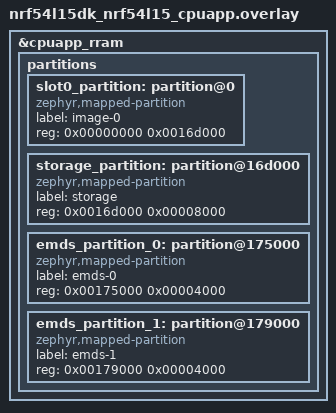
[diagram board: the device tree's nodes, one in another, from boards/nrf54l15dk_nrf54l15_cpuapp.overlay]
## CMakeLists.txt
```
#
# Copyright (c) 2020 Nordic Semiconductor ASA
#
# SPDX-License-Identifier: LicenseRef-Nordic-5-Clause
#
cmake_minimum_required(VERSION 3.20.0)

find_package(Zephyr REQUIRED HINTS $ENV{ZEPHYR_BASE})
project(NONE)

target_sources(app PRIVATE src/main.c)
```

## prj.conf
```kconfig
#
# Copyright (c) 2020 Nordic Semiconductor ASA
#
# SPDX-License-Identifier: LicenseRef-Nordic-5-Clause
#
CONFIG_NCS_SAMPLES_DEFAULTS=y
CONFIG_LOG_MODE_DEFERRED=y

# General configuration
CONFIG_SYSTEM_WORKQUEUE_STACK_SIZE=2048
CONFIG_FLASH=y
CONFIG_FLASH_MAP=y
CONFIG_FCB=y
CONFIG_SETTINGS=y
CONFIG_FPU=y

# Bluetooth configuration
CONFIG_BT=y
CONFIG_BT_L2CAP_TX_MTU=69
CONFIG_BT_L2CAP_TX_BUF_COUNT=8
CONFIG_BT_OBSERVER=y
CONFIG_BT_PERIPHERAL=y

# Bluetooth Mesh configuration
CONFIG_BT_MESH=y
CONFIG_BT_MESH_RELAY=y
CONFIG_BT_MESH_FRIEND=y
CONFIG_BT_MESH_LOW_POWER=y
CONFIG_BT_MESH_PB_GATT=y
CONFIG_BT_MESH_GATT_PROXY=y

# Bluetooth Mesh models
CONFIG_BT_MESH_ONOFF_SRV=y
CONFIG_BT_MESH_ONOFF_CLI=y
CONFIG_BT_MESH_TIME_SRV=y
CONFIG_BT_MESH_TIME_CLI=y
CONFIG_BT_MESH_LVL_SRV=y
CONFIG_BT_MESH_LVL_CLI=y
CONFIG_BT_MESH_DTT_SRV=y
CONFIG_BT_MESH_DTT_CLI=y
CONFIG_BT_MESH_PONOFF_SRV=y
CONFIG_BT_MESH_PONOFF_CLI=y
CONFIG_BT_MESH_PLVL_SRV=y
CONFIG_BT_MESH_PLVL_CLI=y
CONFIG_BT_MESH_BATTERY_SRV=y
CONFIG_BT_MESH_BATTERY_CLI=y
CONFIG_BT_MESH_LOC_SRV=y
CONFIG_BT_MESH_LOC_CLI=y
CONFIG_BT_MESH_PROP_SRV=y
CONFIG_BT_MESH_PROP_CLI=y
CONFIG_BT_MESH_LIGHTNESS_SRV=y
CONFIG_BT_MESH_LIGHTNESS_CLI=y
CONFIG_BT_MESH_LIGHT_CTRL_SRV=y
CONFIG_BT_MESH_LIGHT_CTRL_CLI=y
CONFIG_BT_MESH_LIGHT_CTL_CLI=y
CONFIG_BT_MESH_LIGHT_CTL_SRV=y
CONFIG_BT_MESH_LIGHT_TEMP_SRV=y
CONFIG_BT_MESH_SENSOR_SRV=y
CONFIG_BT_MESH_SENSOR_CLI=y
CONFIG_BT_MESH_SCENE_CLI=y
CONFIG_BT_MESH_LIGHT_XYL_SRV=y
CONFIG_BT_MESH_LIGHT_XYL_CLI=y
CONFIG_BT_MESH_LIGHT_HUE_SRV=y
CONFIG_BT_MESH_LIGHT_SAT_SRV=y
CONFIG_BT_MESH_LIGHT_HSL_SRV=y
CONFIG_BT_MESH_LIGHT_HSL_CLI=y
CONFIG_BT_MESH_SCHEDULER_CLI=y
```

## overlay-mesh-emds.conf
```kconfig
#
# Copyright (c) 2024 Nordic Semiconductor ASA
#
# SPDX-License-Identifier: LicenseRef-Nordic-5-Clause
#

CONFIG_BT_SETTINGS=y
CONFIG_FLASH_MAP=y
CONFIG_NVS=y
CONFIG_EMDS=y
CONFIG_BT_MESH_PLVL_SRV=y
CONFIG_BT_MESH_LIGHT_HUE_SRV=y
CONFIG_BT_MESH_LIGHT_SAT_SRV=y
CONFIG_BT_MESH_LIGHT_TEMP_SRV=y
CONFIG_BT_MESH_LIGHT_XYL_SRV=y
CONFIG_BT_MESH_LIGHTNESS_SRV=y
CONFIG_BT_MESH_ONOFF_SRV=n
CONFIG_BT_MESH_ONOFF_CLI=n
CONFIG_BT_MESH_TIME_SRV=n
CONFIG_BT_MESH_TIME_CLI=n
CONFIG_BT_MESH_LVL_SRV=n
CONFIG_BT_MESH_LVL_CLI=n
CONFIG_BT_MESH_DTT_SRV=n
CONFIG_BT_MESH_DTT_CLI=n
CONFIG_BT_MESH_PONOFF_SRV=n
CONFIG_BT_MESH_PONOFF_CLI=n
CONFIG_BT_MESH_PLVL_CLI=n
CONFIG_BT_MESH_BATTERY_SRV=n
CONFIG_BT_MESH_BATTERY_CLI=n
CONFIG_BT_MESH_LOC_SRV=n
CONFIG_BT_MESH_LOC_CLI=n
CONFIG_BT_MESH_PROP_SRV=n
CONFIG_BT_MESH_PROP_CLI=n
CONFIG_BT_MESH_LIGHTNESS_CLI=n
CONFIG_BT_MESH_LIGHT_CTRL_SRV=y
CONFIG_BT_MESH_LIGHT_CTRL_CLI=n
CONFIG_BT_MESH_LIGHT_CTL_CLI=n
CONFIG_BT_MESH_LIGHT_CTL_SRV=n
CONFIG_BT_MESH_SENSOR_SRV=n
CONFIG_BT_MESH_SENSOR_CLI=n
CONFIG_BT_MESH_SCENE_CLI=n
CONFIG_BT_MESH_LIGHT_XYL_CLI=n
CONFIG_BT_MESH_LIGHT_HSL_SRV=n
CONFIG_BT_MESH_LIGHT_HSL_CLI=n
```

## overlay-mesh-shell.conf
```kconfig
#
# Copyright (c) 2024 Nordic Semiconductor ASA
#
# SPDX-License-Identifier: LicenseRef-Nordic-5-Clause
#

CONFIG_BT_MESH_SHELL=y
CONFIG_BT_MESH_SHELL_ONOFF_CLI=y
CONFIG_BT_MESH_SHELL_LVL_CLI=y
CONFIG_BT_MESH_SHELL_DTT_CLI=y
CONFIG_BT_MESH_SHELL_PONOFF_CLI=y
CONFIG_BT_MESH_SHELL_PLVL_CLI=y
CONFIG_BT_MESH_SHELL_BATTERY_CLI=y
CONFIG_BT_MESH_SHELL_LOC_CLI=y
CONFIG_BT_MESH_SHELL_PROP_CLI=y
CONFIG_BT_MESH_SHELL_LIGHTNESS_CLI=y
CONFIG_BT_MESH_SHELL_LIGHT_CTL_CLI=y
CONFIG_BT_MESH_SHELL_LIGHT_HSL_CLI=y
CONFIG_BT_MESH_SHELL_LIGHT_XYL_CLI=y
CONFIG_BT_MESH_SHELL_LIGHT_CTRL_CLI=y
CONFIG_BT_MESH_SHELL_TIME_CLI=y
CONFIG_BT_MESH_SHELL_SCENE_CLI=y
CONFIG_BT_MESH_SHELL_SCHEDULER_CLI=y
CONFIG_BT_MESH_SHELL_SENSOR_CLI=y
```

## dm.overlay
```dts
/*
 * Copyright (c) 2024 Nordic Semiconductor ASA
 *
 * SPDX-License-Identifier: LicenseRef-Nordic-5-Clause
 */

/ {
	/* The timer instance to use. */
	chosen {
		ncs,dm-timer = &timer2;
	};
};
```

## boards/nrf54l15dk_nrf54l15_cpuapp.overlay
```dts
/*
 * Copyright (c) 2026 Nordic Semiconductor ASA
 *
 * SPDX-License-Identifier: LicenseRef-Nordic-5-Clause
 */

/delete-node/ &boot_partition;
/delete-node/ &slot0_partition;
/delete-node/ &slot1_partition;
/delete-node/ &storage_partition;

&cpuapp_rram {
	partitions {
		slot0_partition: partition@0 {
			compatible = "zephyr,mapped-partition";
			label = "image-0";
			reg = <0x00000000 0x0016d000>;
		};

		storage_partition: partition@16d000 {
			compatible = "zephyr,mapped-partition";
			label = "storage";
			reg = <0x0016d000 0x00008000>;
		};

		emds_partition_0: partition@175000 {
			compatible = "zephyr,mapped-partition";
			label = "emds-0";
			reg = <0x00175000 0x00004000>;
		};

		emds_partition_1: partition@179000 {
			compatible = "zephyr,mapped-partition";
			label = "emds-1";
			reg = <0x00179000 0x00004000>;
		};
	};
};
```

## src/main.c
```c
/*
 * Copyright (c) 2020 Nordic Semiconductor ASA
 *
 * SPDX-License-Identifier: LicenseRef-Nordic-5-Clause
 */

#include <zephyr/bluetooth/mesh.h>
#include <bluetooth/mesh/models.h>

/* Instantiate all models, using their INIT macros if available. */
#if !defined CONFIG_EMDS
static struct bt_mesh_lvl_srv lvl_srv = BT_MESH_LVL_SRV_INIT(NULL);
static struct bt_mesh_ponoff_srv ponoff_srv =
	BT_MESH_PONOFF_SRV_INIT(NULL, NULL, NULL);
static struct bt_mesh_light_ctrl_srv light_ctrl_srv =
	BT_MESH_LIGHT_CTRL_SRV_INIT(NULL);
static struct bt_mesh_light_ctl_srv light_ctl_srv =
	BT_MESH_LIGHT_CTL_SRV_INIT(NULL, NULL);
static struct bt_mesh_onoff_srv onoff_srv = BT_MESH_ONOFF_SRV_INIT(NULL);
static struct bt_mesh_onoff_cli onoff_cli = BT_MESH_ONOFF_CLI_INIT(NULL);
static struct bt_mesh_time_srv time_srv = BT_MESH_TIME_SRV_INIT(NULL);
static struct bt_mesh_time_cli time_cli = BT_MESH_TIME_CLI_INIT(NULL);
static struct bt_mesh_lvl_cli lvl_cli = BT_MESH_LVL_CLI_INIT(NULL);
static struct bt_mesh_dtt_srv dtt_srv = BT_MESH_DTT_SRV_INIT(NULL);
static struct bt_mesh_dtt_cli dtt_cli = BT_MESH_DTT_CLI_INIT(NULL);
static struct bt_mesh_ponoff_cli ponoff_cli = BT_MESH_PONOFF_CLI_INIT(NULL);
static struct bt_mesh_plvl_cli plvl_cli = BT_MESH_PLVL_CLI_INIT(NULL);
static struct bt_mesh_battery_srv battery_srv = BT_MESH_BATTERY_SRV_INIT(NULL);
static struct bt_mesh_battery_cli battery_cli = BT_MESH_BATTERY_CLI_INIT(NULL);
static struct bt_mesh_loc_srv loc_srv = BT_MESH_LOC_SRV_INIT(NULL);
static struct bt_mesh_loc_cli loc_cli = BT_MESH_LOC_CLI_INIT(NULL);
static struct bt_mesh_prop_srv prop_srv = BT_MESH_PROP_SRV_USER_INIT();
static struct bt_mesh_prop_cli prop_cli = BT_MESH_PROP_CLI_INIT(NULL, NULL);
static struct bt_mesh_lightness_cli lightness_cli =
	BT_MESH_LIGHTNESS_CLI_INIT(NULL);
static struct bt_mesh_light_ctrl_cli light_ctrl_cli =
	BT_MESH_LIGHT_CTRL_CLI_INIT(NULL);
static struct bt_mesh_light_ctl_cli light_ctl_cli =
	BT_MESH_LIGHT_CTL_CLI_INIT(NULL);
static struct bt_mesh_sensor_cli sensor_cli = BT_MESH_SENSOR_CLI_INIT(NULL);
static struct bt_mesh_scene_cli scene_cli;
static struct bt_mesh_light_xyl_cli xyl_cli;
static struct bt_mesh_light_hsl_cli light_hsl_cli;
static struct bt_mesh_light_hsl_srv light_hsl_srv =
	BT_MESH_LIGHT_HSL_SRV_INIT(NULL, NULL, NULL);
static struct bt_mesh_scheduler_cli scheduler_cli;
/* Settings dependent models: */
#ifdef CONFIG_BT_SETTINGS
static struct bt_mesh_scene_srv scene_srv;
static struct bt_mesh_scheduler_srv scheduler_srv =
	BT_MESH_SCHEDULER_SRV_INIT(NULL, &time_srv);
#endif
#endif /* !defined CONFIG_EMDS */
static struct bt_mesh_plvl_srv plvl_srv = BT_MESH_PLVL_SRV_INIT(NULL);
static struct bt_mesh_light_hue_srv light_hue_srv =
	BT_MESH_LIGHT_HUE_SRV_INIT(NULL);
static struct bt_mesh_light_sat_srv light_sat_srv =
	BT_MESH_LIGHT_SAT_SRV_INIT(NULL);
static struct bt_mesh_light_xyl_srv xyl_srv =
	BT_MESH_LIGHT_XYL_SRV_INIT(NULL, NULL);
static struct bt_mesh_light_temp_srv light_temp_srv =
	BT_MESH_LIGHT_TEMP_SRV_INIT(NULL);
static struct bt_mesh_lightness_srv lightness_srv =
	BT_MESH_LIGHTNESS_SRV_INIT(NULL);

static struct bt_mesh_elem elems[] = {
	BT_MESH_ELEM(0, BT_MESH_MODEL_LIST(
#if !defined CONFIG_EMDS
#ifdef CONFIG_BT_SETTINGS
		BT_MESH_MODEL_SCENE_SRV(&scene_srv),
		BT_MESH_MODEL_SCHEDULER_SRV(&scheduler_srv),
#endif
		BT_MESH_MODEL_LVL_SRV(&lvl_srv),
		BT_MESH_MODEL_PONOFF_SRV(&ponoff_srv),
		BT_MESH_MODEL_LIGHT_CTRL_SRV(&light_ctrl_srv),
		BT_MESH_MODEL_LIGHT_CTL_SRV(&light_ctl_srv),
		BT_MESH_MODEL_ONOFF_SRV(&onoff_srv),
		BT_MESH_MODEL_ONOFF_CLI(&onoff_cli),
		BT_MESH_MODEL_TIME_SRV(&time_srv),
		BT_MESH_MODEL_TIME_CLI(&time_cli),
		BT_MESH_MODEL_LVL_CLI(&lvl_cli),
		BT_MESH_MODEL_DTT_SRV(&dtt_srv),
		BT_MESH_MODEL_DTT_CLI(&dtt_cli),
		BT_MESH_MODEL_PONOFF_CLI(&ponoff_cli),
		BT_MESH_MODEL_PLVL_CLI(&plvl_cli),
		BT_MESH_MODEL_BATTERY_SRV(&battery_srv),
		BT_MESH_MODEL_BATTERY_CLI(&battery_cli),
		BT_MESH_MODEL_LOC_SRV(&loc_srv),
		BT_MESH_MODEL_LOC_CLI(&loc_cli),
		BT_MESH_MODEL_PROP_SRV_USER(&prop_srv),
		BT_MESH_MODEL_PROP_CLI(&prop_cli),
		BT_MESH_MODEL_LIGHTNESS_CLI(&lightness_cli),
		BT_MESH_MODEL_LIGHT_CTRL_CLI(&light_ctrl_cli),
		BT_MESH_MODEL_LIGHT_CTL_CLI(&light_ctl_cli),
		BT_MESH_MODEL_SENSOR_CLI(&sensor_cli),
		BT_MESH_MODEL_SCENE_CLI(&scene_cli),
		BT_MESH_MODEL_LIGHT_XYL_CLI(&xyl_cli),
		BT_MESH_MODEL_LIGHT_HSL_CLI(&light_hsl_cli),
		BT_MESH_MODEL_LIGHT_HSL_SRV(&light_hsl_srv),
		BT_MESH_MODEL_SCHEDULER_CLI(&scheduler_cli),
#endif /* !defined CONFIG_EMDS */
		BT_MESH_MODEL_PLVL_SRV(&plvl_srv),
		BT_MESH_MODEL_LIGHT_HUE_SRV(&light_hue_srv),
		BT_MESH_MODEL_LIGHT_SAT_SRV(&light_sat_srv),
		BT_MESH_MODEL_LIGHT_TEMP_SRV(&light_temp_srv),
		BT_MESH_MODEL_LIGHT_XYL_SRV(&xyl_srv),
		BT_MESH_MODEL_LIGHTNESS_SRV(&lightness_srv)
	), BT_MESH_MODEL_NONE),
};

static const struct bt_mesh_comp comp = {
	.elem = elems,
	.elem_count = ARRAY_SIZE(elems),
};

int main(void)
{
	int err;

	err = bt_mesh_init(NULL, &comp);
	__ASSERT_NO_MSG(err == 0);

	return 0;
}
```
